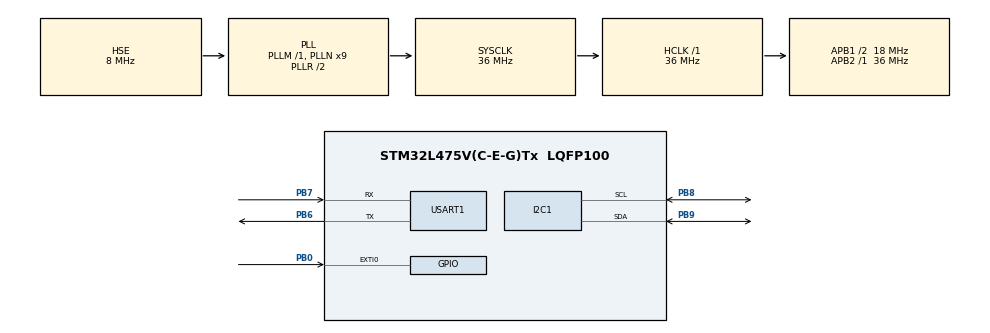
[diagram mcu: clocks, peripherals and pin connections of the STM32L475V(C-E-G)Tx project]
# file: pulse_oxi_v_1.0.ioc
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I2C1.Timing=0x00404567
Mcu.Family=STM32L4
Mcu.Name=STM32L475V(C-E-G)Tx
Mcu.Package=LQFP100
NVIC.EXTI0_IRQn=true\:0\:0\:false\:false\:true\:true\:true
NVIC.PriorityGroup=NVIC_PRIORITYGROUP_4
NVIC.TIM1_TRG_COM_TIM17_IRQn=true\:0\:0\:false\:false\:true\:false\:true
NVIC.TimeBase=TIM1_TRG_COM_TIM17_IRQn
NVIC.TimeBaseIP=TIM17
PA13\ (JTMS-SWDIO).Mode=Serial_Wire
PA13\ (JTMS-SWDIO).Signal=SYS_JTMS-SWDIO
PA14\ (JTCK-SWCLK).Mode=Serial_Wire
PA14\ (JTCK-SWCLK).Signal=SYS_JTCK-SWCLK
PB0.GPIO_ModeDefaultEXTI=GPIO_MODE_IT_FALLING
PB0.GPIO_PuPd=GPIO_PULLUP
PB0.Signal=GPXTI0
PB6.Mode=Asynchronous
PB6.Signal=USART1_TX
PB7.Mode=Asynchronous
PB7.Signal=USART1_RX
PB8.Mode=I2C
PB8.Signal=I2C1_SCL
PB9.Mode=I2C
PB9.Signal=I2C1_SDA
PH0-OSC_IN\ (PH0).Mode=HSE-External-Oscillator
PH0-OSC_IN\ (PH0).Signal=RCC_OSC_IN
PH1-OSC_OUT\ (PH1).Mode=HSE-External-Oscillator
PH1-OSC_OUT\ (PH1).Signal=RCC_OSC_OUT
ProjectManager.HeapSize=0x200
ProjectManager.StackSize=0x400
ProjectManager.TargetToolchain=STM32CubeIDE
RCC.ADCFreq_Value=32000000
RCC.AHBFreq_Value=36000000
RCC.APB1CLKDivider=RCC_HCLK_DIV2
RCC.APB1Freq_Value=18000000
RCC.APB1TimFreq_Value=36000000
RCC.APB2Freq_Value=36000000
RCC.APB2TimFreq_Value=36000000
RCC.CortexFreq_Value=36000000
RCC.HCLKFreq_Value=36000000
RCC.HSE_VALUE=8000000
RCC.HSI_VALUE=16000000
RCC.LSE_VALUE=32768
RCC.MSI_VALUE=4000000
RCC.PLLN=9
RCC.PLLSourceVirtual=RCC_PLLSOURCE_HSE
RCC.SYSCLKFreq_VALUE=36000000
RCC.SYSCLKSource=RCC_SYSCLKSOURCE_PLLCLK
RCC.USBFreq_Value=32000000
RCC.VCOOutputFreq_Value=72000000
USART1.VirtualMode-Asynchronous=VM_ASYNC
VP_SYS_VS_tim17.Mode=TIM17
board=custom

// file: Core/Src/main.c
/* USER CODE BEGIN Header */
/**
 ******************************************************************************
 * @file           : main.c
 * @brief          : Main program body
 ******************************************************************************
 * @attention
 *
 * <h2><center>&copy; Copyright (c) 2020 STMicroelectronics.
 * All rights reserved.</center></h2>
 *
 * This software component is licensed by ST under BSD 3-Clause license,
 * the "License"; You may not use this file except in compliance with the
 * License. You may obtain a copy of the License at:
 *                        opensource.org/licenses/BSD-3-Clause
 *
 ******************************************************************************
 */
/* USER CODE END Header */
#include "main.h"
#include "max30100_for_stm32_hal.h"
/* USER CODE BEGIN Includes */
#include <string.h>
#include <stdio.h>
#include <retarget.h>
/* USER CODE END Includes */

I2C_HandleTypeDef hi2c1;

UART_HandleTypeDef huart1;

void SystemClock_Config(void);
static void MX_GPIO_Init(void);
static void MX_USART1_UART_Init(void);
static void MX_I2C1_Init(void);

/* USER CODE BEGIN 0 */

uint8_t count = 0;
/* USER CODE END 0 */

int main(void)
{

  /* MCU Configuration--------------------------------------------------------*/

  /* Reset of all peripherals, Initializes the Flash interface and the Systick. */
  HAL_Init();

  /* Configure the system clock */
  SystemClock_Config();

  /* Initialize all configured peripherals */
  MX_GPIO_Init();
  MX_USART1_UART_Init();
  MX_I2C1_Init();
  /* USER CODE BEGIN 2 */
  RetargetInit(&huart1);
  /* USER CODE END 2 */

  /* Infinite loop */
  /* USER CODE BEGIN WHILE */
	while (1)
	{
		count++;
		printf("\r\nCount %d",count);
		HAL_Delay(250);
    /* USER CODE END WHILE */

	}
}

void SystemClock_Config(void)
{
  RCC_OscInitTypeDef RCC_OscInitStruct = {0};
  RCC_ClkInitTypeDef RCC_ClkInitStruct = {0};
  RCC_PeriphCLKInitTypeDef PeriphClkInit = {0};

  /** Initializes the RCC Oscillators according to the specified parameters
  * in the RCC_OscInitTypeDef structure.
  */
  RCC_OscInitStruct.OscillatorType = RCC_OSCILLATORTYPE_HSE;
  RCC_OscInitStruct.HSEState = RCC_HSE_ON;
  RCC_OscInitStruct.PLL.PLLState = RCC_PLL_ON;
  RCC_OscInitStruct.PLL.PLLSource = RCC_PLLSOURCE_HSE;
  RCC_OscInitStruct.PLL.PLLM = 1;
  RCC_OscInitStruct.PLL.PLLN = 9;
  RCC_OscInitStruct.PLL.PLLP = RCC_PLLP_DIV7;
  RCC_OscInitStruct.PLL.PLLQ = RCC_PLLQ_DIV2;
  RCC_OscInitStruct.PLL.PLLR = RCC_PLLR_DIV2;
  if (HAL_RCC_OscConfig(&RCC_OscInitStruct) != HAL_OK)
  {
    Error_Handler();
  }
  /** Initializes the CPU, AHB and APB buses clocks
  */
  RCC_ClkInitStruct.ClockType = RCC_CLOCKTYPE_HCLK|RCC_CLOCKTYPE_SYSCLK
                              |RCC_CLOCKTYPE_PCLK1|RCC_CLOCKTYPE_PCLK2;
  RCC_ClkInitStruct.SYSCLKSource = RCC_SYSCLKSOURCE_PLLCLK;
  RCC_ClkInitStruct.AHBCLKDivider = RCC_SYSCLK_DIV1;
  RCC_ClkInitStruct.APB1CLKDivider = RCC_HCLK_DIV2;
  RCC_ClkInitStruct.APB2CLKDivider = RCC_HCLK_DIV1;

  if (HAL_RCC_ClockConfig(&RCC_ClkInitStruct, FLASH_LATENCY_2) != HAL_OK)
  {
    Error_Handler();
  }
  PeriphClkInit.PeriphClockSelection = RCC_PERIPHCLK_USART1|RCC_PERIPHCLK_I2C1;
  PeriphClkInit.Usart1ClockSelection = RCC_USART1CLKSOURCE_PCLK2;
  PeriphClkInit.I2c1ClockSelection = RCC_I2C1CLKSOURCE_PCLK1;
  if (HAL_RCCEx_PeriphCLKConfig(&PeriphClkInit) != HAL_OK)
  {
    Error_Handler();
  }
  /** Configure the main internal regulator output voltage
  */
  if (HAL_PWREx_ControlVoltageScaling(PWR_REGULATOR_VOLTAGE_SCALE1) != HAL_OK)
  {
    Error_Handler();
  }
}

static void MX_I2C1_Init(void)
{

  hi2c1.Instance = I2C1;
  hi2c1.Init.Timing = 0x00404567;
  hi2c1.Init.OwnAddress1 = 0;
  hi2c1.Init.AddressingMode = I2C_ADDRESSINGMODE_7BIT;
  hi2c1.Init.DualAddressMode = I2C_DUALADDRESS_DISABLE;
  hi2c1.Init.OwnAddress2 = 0;
  hi2c1.Init.OwnAddress2Masks = I2C_OA2_NOMASK;
  hi2c1.Init.GeneralCallMode = I2C_GENERALCALL_DISABLE;
  hi2c1.Init.NoStretchMode = I2C_NOSTRETCH_DISABLE;
  if (HAL_I2C_Init(&hi2c1) != HAL_OK)
  {
    Error_Handler();
  }
  /** Configure Analogue filter
  */
  if (HAL_I2CEx_ConfigAnalogFilter(&hi2c1, I2C_ANALOGFILTER_ENABLE) != HAL_OK)
  {
    Error_Handler();
  }
  /** Configure Digital filter
  */
  if (HAL_I2CEx_ConfigDigitalFilter(&hi2c1, 0) != HAL_OK)
  {
    Error_Handler();
  }

}

static void MX_USART1_UART_Init(void)
{

  huart1.Instance = USART1;
  huart1.Init.BaudRate = 115200;
  huart1.Init.WordLength = UART_WORDLENGTH_8B;
  huart1.Init.StopBits = UART_STOPBITS_1;
  huart1.Init.Parity = UART_PARITY_NONE;
  huart1.Init.Mode = UART_MODE_TX_RX;
  huart1.Init.HwFlowCtl = UART_HWCONTROL_NONE;
  huart1.Init.OverSampling = UART_OVERSAMPLING_16;
  huart1.Init.OneBitSampling = UART_ONE_BIT_SAMPLE_DISABLE;
  huart1.AdvancedInit.AdvFeatureInit = UART_ADVFEATURE_NO_INIT;
  if (HAL_UART_Init(&huart1) != HAL_OK)
  {
    Error_Handler();
  }

}

static void MX_GPIO_Init(void)
{
  GPIO_InitTypeDef GPIO_InitStruct = {0};

  /* GPIO Ports Clock Enable */
  __HAL_RCC_GPIOH_CLK_ENABLE();
  __HAL_RCC_GPIOB_CLK_ENABLE();
  __HAL_RCC_GPIOA_CLK_ENABLE();

  /*Configure GPIO pin : PB0 */
  GPIO_InitStruct.Pin = GPIO_PIN_0;
  GPIO_InitStruct.Mode = GPIO_MODE_IT_FALLING;
  GPIO_InitStruct.Pull = GPIO_PULLUP;
  HAL_GPIO_Init(GPIOB, &GPIO_InitStruct);

  /* EXTI interrupt init*/
  HAL_NVIC_SetPriority(EXTI0_IRQn, 0, 0);
  HAL_NVIC_EnableIRQ(EXTI0_IRQn);

}

void HAL_TIM_PeriodElapsedCallback(TIM_HandleTypeDef *htim)
{
  if (htim->Instance == TIM17) {
    HAL_IncTick();
  }
}

void Error_Handler(void)
{
}

/************************ (C) COPYRIGHT STMicroelectronics *****END OF FILE****/
